AUTOSAR XML (schema 00049)
package /RB/PT/PCT_DcmSample_Provider/SwComponentTypes
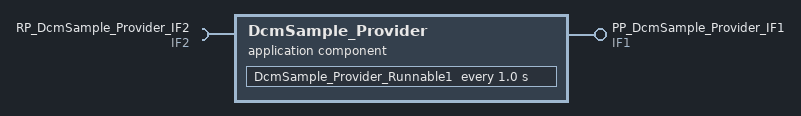
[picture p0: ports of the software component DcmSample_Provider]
  application sw component type DcmSample_Provider
    provide port PP_DcmSample_Provider_IF1: provided-interface=IF1
    require port RP_DcmSample_Provider_IF2: required-interface=IF2
    behavior IB_DcmSample_Provider: data-type-mapping=[DTMS_DcmSample_Provider, DTMS_DcmSample_Requirer]
      timing event DcmSample_Provider_Runnable1_TimingEvent: start-on-event=DcmSample_Provider_Runnable1, period=1.0
      runnable DcmSample_Provider_Runnable1: reentrancy-level=NON-REENTRANT, symbol=DcmSample_Provider_Runnable1_fnc
        data-receive-point-by-values:
          access DcmSample_Provider_Runnable1_RP_IF2: accessed-variable=RP_DcmSample_Provider_IF2.IF2_var1
        data-send-points:
          access DcmSample_Provider_Runnable1_PP_IF1: accessed-variable=PP_DcmSample_Provider_IF1.IF1_var1
package /RB/PT/PCT_DcmSample_Provider/PortInterfaces
  sender receiver interface IF1
    data IF1_var1: sw-calibration-access=READ-ONLY, type=uint8
package /RB/PT/PCT_DcmSample_Provider/ApplicationDataTypes
  app type uint8: category=VALUE, sw-calibration-access=READ-WRITE, range phys 0..255 RBPtCel_NoUnit
package /RB/PT/PCT_DcmSample_Provider/DataTypeMappingSets
  data type mapping set DTMS_DcmSample_Provider: data-type-map{application-data-type=uint8, implementation-data-type=uint8}
